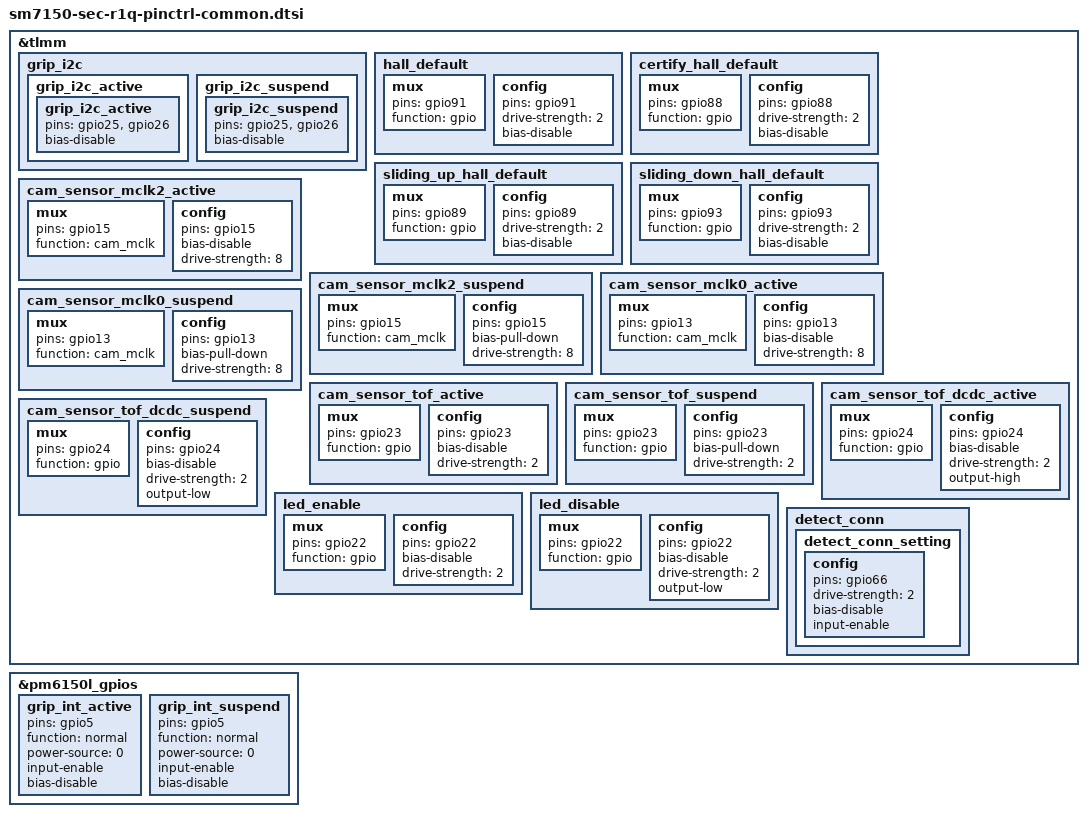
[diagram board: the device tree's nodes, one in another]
/* Copyright (c) 2018, The Linux Foundation. All rights reserved.
 *
 * This program is free software; you can redistribute it and/or modify
 * it under the terms of the GNU General Public License version 2 and
 * only version 2 as published by the Free Software Foundation.
 *
 * This program is distributed in the hope that it will be useful,
 * but WITHOUT ANY WARRANTY; without even the implied warranty of
 * MERCHANTABILITY or FITNESS FOR A PARTICULAR PURPOSE.  See the
 * GNU General Public License for more details.
 */

#include "sm7150-sec-r1q-audio-pinctrl.dtsi"

&tlmm {
        grip_i2c {
		grip_i2c_active: grip_i2c_active {
			grip_i2c_active {
				pins = "gpio25", "gpio26";
				bias-disable;
			};
		};
		grip_i2c_suspend: grip_i2c_suspend {
			grip_i2c_suspend {
				pins = "gpio25", "gpio26";
				bias-disable;
			};
		};
	};

	hall_default: hall_default {
		mux {
			pins = "gpio91";
			function = "gpio";
		};
		config {
			pins = "gpio91";
			drive-strength = <2>;
			bias-disable;
		};
	};

	certify_hall_default: certify_hall_default {
		mux {
			pins = "gpio88";
			function = "gpio";
		};
		config {
			pins = "gpio88";
			drive-strength = <2>;
			bias-disable;
		};
	};

	sliding_up_hall_default: sliding_up_hall_default {
		mux {
			pins = "gpio89";
			function = "gpio";
		};
		config {
			pins = "gpio89";
			drive-strength = <2>;
			bias-disable;
		};
	};

	sliding_down_hall_default: sliding_down_hall_default {
		mux {
			pins = "gpio93";
			function = "gpio";
		};
		config {
			pins = "gpio93";
			drive-strength = <2>;
			bias-disable;
		};
	};
	cam_sensor_mclk2_active: cam_sensor_mclk2_active {
		/* MCLK2 */
		mux {
			pins = "gpio15";
			function = "cam_mclk";
		};

		config {
			pins = "gpio15";
			bias-disable; /* No PULL */
			drive-strength = <8>; /* 8 MA */
		};
	};
	cam_sensor_mclk2_suspend: cam_sensor_mclk2_suspend {
		/* MCLK2 */
		mux {
			pins = "gpio15";
			function = "cam_mclk";
		};

		config {
			pins = "gpio15";
			bias-pull-down; /* PULL DOWN */
			drive-strength = <8>; /* 8 MA */
		};
	};
	cam_sensor_mclk0_active: cam_sensor_mclk0_active {
      	/* TOF MCLK */
		mux {
			pins = "gpio13";
			function = "cam_mclk";
		};
		config {
			pins = "gpio13";
			bias-disable; /* No PULL */
			drive-strength = <8>; /* 8 MA */
		};
	};

	cam_sensor_mclk0_suspend: cam_sensor_mclk0_suspend {
	/* TOF MCLK */
		mux {
			pins = "gpio13";
			function = "cam_mclk";
		};
		config {
			pins = "gpio13";
			bias-pull-down; /* No PULL */
			drive-strength = <8>; /* 8 MA */
		};
	};

	cam_sensor_tof_active: cam_sensor_tof_active {
	/* TOF reset */
		mux {
			pins = "gpio23";
			function = "gpio";
		};
		config {
			pins = "gpio23";
			bias-disable; /* No PULL */
			drive-strength = <2>; /* 2 MA */
		};
	};
	cam_sensor_tof_suspend: cam_sensor_tof_suspend {
	/* TOF reset */
		mux {
			pins = "gpio23";
			function = "gpio";
		};
		config {
			pins = "gpio23";
			bias-pull-down; /* PULL DOWN */
			drive-strength = <2>; /* 2 MA */
		};
	};
	cam_sensor_tof_dcdc_active: cam_sensor_tof_dcdc_active {
	/* TOF dcdc */
		mux {
			pins = "gpio24";
			function = "gpio";
		};
		config {
			pins = "gpio24";
			bias-disable; /* No PULL */
			drive-strength = <2>; /* 2 MA */
			output-high;
		};
	};
	cam_sensor_tof_dcdc_suspend: cam_sensor_tof_dcdc_suspend {
	/* TOF dcdc */
		mux {
			pins = "gpio24";
			function = "gpio";
		};
		config {
			pins = "gpio24";
			bias-disable; /* No PULL */
			drive-strength = <2>; /* 2 MA */
			output-low;
		};
	};

	led_enable: led_enable {
		mux {
			pins = "gpio22";
			function = "gpio";
		};

		config {
			pins = "gpio22";
			bias-disable; /* No PULL */
			drive-strength = <2>; /* 2 MA */
		};
	};

	led_disable: led_disable {
		mux {
			pins = "gpio22";
			function = "gpio";
		};

		config {
			pins = "gpio22";
			bias-disable; /* No PULL */
			drive-strength = <2>; /* 2 MA */
			output-low;
		};
	};

	detect_conn {
		detect_conn_setting: detect_conn_setting {
			config {
				pins = "gpio66";
				drive-strength = <2>;
				bias-disable; /* No PULL */
				input-enable;
			};
		};
	};
};

&pm6150l_gpios {
	grip_int_active: grip_int_active {
		pins = "gpio5";
		function = "normal";
		power-source = <0>;
		input-enable;
		bias-disable;
	};
	grip_int_suspend: grip_int_suspend {
		pins = "gpio5";
		function = "normal";
		power-source = <0>;
		input-enable;
		bias-disable;
	};
};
